# PIC32CX5109BZ31048_SL3 register map
Vendor: Microchip Technology; Series: PIC32CXBZ31; File version: 0
CPU: CM4 r0p1, little endian, MPU, FPU, 3 interrupt priority bits, 43 interrupts
Registers are 32-bit, read-write, reset 0x0 unless marked. A register's access mark holds for its fields unless they carry their own. Offsets are from the block's base; [hi:lo] are bit positions; lines under a group give offsets from that group; {n}, {i} and the like mark numbered series.

## EVSYS — Event System Interface
Base 0x41006000
0x00 CTRLA 8-bit — Control
  [0] SWRST — Software Reset
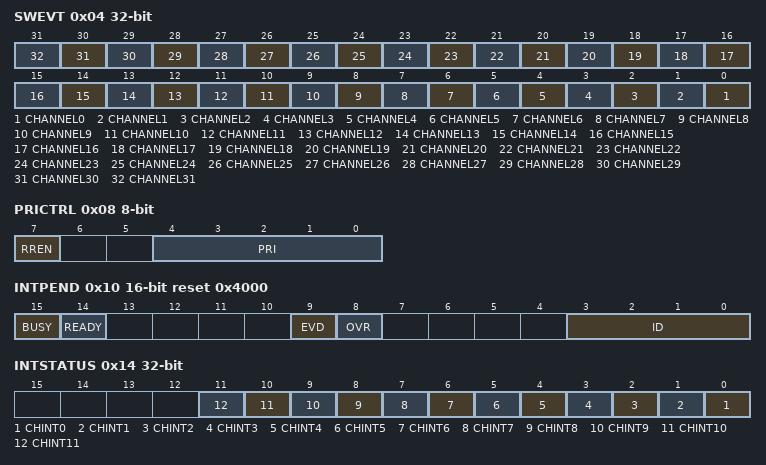
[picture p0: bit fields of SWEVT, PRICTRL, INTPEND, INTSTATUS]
0x04 SWEVT wo — Software Event
  [n] CHANNEL{n} (n=0..31) — Channel {n} Software Selection
0x08 PRICTRL 8-bit — Priority Control
  [7] RREN — Round-Robin Scheduling Enable
  [4:0] PRI — Channel Priority Number
0x10 INTPEND 16-bit reset 0x4000 — Channel Pending Interrupt
  [15] BUSY
  [14] READY
  [9] EVD — Channel Event Detected
  [8] OVR — Channel Overrun
  [3:0] ID — Channel ID
0x14 INTSTATUS ro — Interrupt Status
  [n] CHINT{n} (n=0..11) — Channel {n} Pending Interrupt
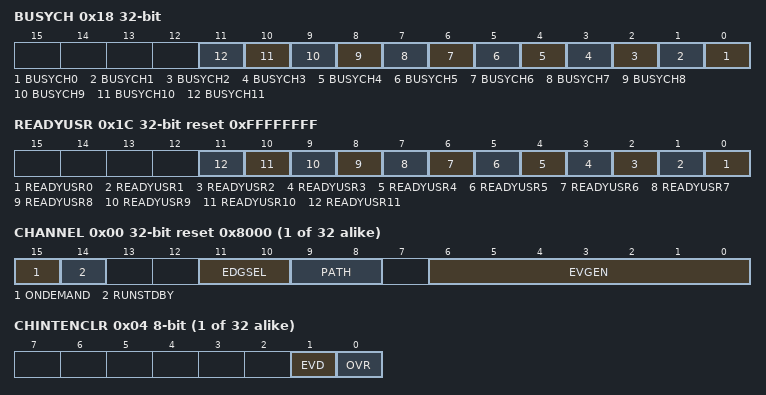
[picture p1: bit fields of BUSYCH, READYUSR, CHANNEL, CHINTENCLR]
0x18 BUSYCH ro — Busy Channels
  [n] BUSYCH{n} (n=0..11) — Busy Channel {n}
0x1C READYUSR ro reset 0xFFFFFFFF — Ready Users
  [n] READYUSR{n} (n=0..11) — Ready User for Channel {n}
{0x20+8i} CHANNEL[{i}] (i=0..31) group
  0x00 CHANNEL reset 0x8000 — Channel n Control
    [15] ONDEMAND — Generic Clock On Demand
    [14] RUNSTDBY — Run in standby
    [11:10] EDGSEL — Edge Detection Selection
      0=NO_EVT_OUTPUT (No event output when using the resynchronized or synchronous path); 1=RISING_EDGE (Event detection only on the rising edge of the signal from the event generator when using the resynchronized or synchronous path); 2=FALLING_EDGE (Event detection only on the falling edge of the signal from the event generator when using the resynchronized or synchronous path); 3=BOTH_EDGES (Event detection on rising and falling edges of the signal from the event generator when using the resynchronized or synchronous path)
    [9:8] PATH — Path Selection
      0=SYNCHRONOUS (Synchronous path); 1=RESYNCHRONIZED (Resynchronized path); 2=ASYNCHRONOUS (Asynchronous path)
    [6:0] EVGEN — Event Generator Selection
  0x04 CHINTENCLR 8-bit write-1-clears — Channel n Interrupt Enable Clear
    [1] EVD — Channel Event Detected Interrupt Disable
    [0] OVR — Channel Overrun Interrupt Disable
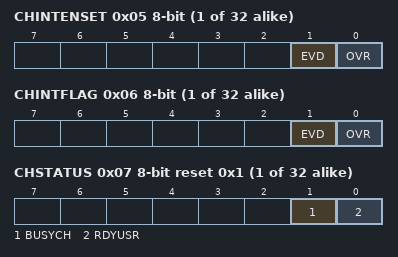
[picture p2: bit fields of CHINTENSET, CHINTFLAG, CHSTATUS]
  0x05 CHINTENSET 8-bit write-1-sets — Channel n Interrupt Enable Set
    [1] EVD — Channel Event Detected Interrupt Enable
    [0] OVR — Channel Overrun Interrupt Enable
  0x06 CHINTFLAG 8-bit write-1-clears — Channel n Interrupt Flag Status and Clear
    [1] EVD — Channel Event Detected
    [0] OVR — Channel Overrun
  0x07 CHSTATUS 8-bit ro reset 0x1 — Channel n Status
    [1] BUSYCH — Busy Channel
    [0] RDYUSR — Ready User
{0x120+4i} USER[{i}] (i=0..56) — User Multiplexer n
  [5:0] CHANNEL — Channel Event Selection

## FPU — Floating Point Unit
Base 0xE000EF30
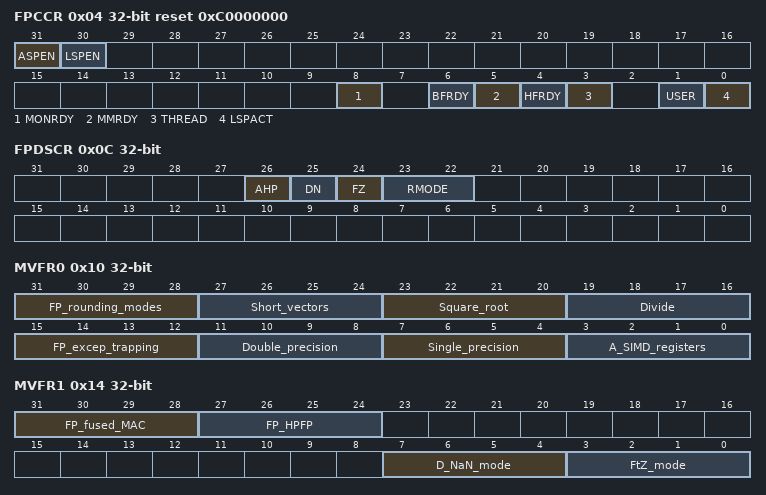
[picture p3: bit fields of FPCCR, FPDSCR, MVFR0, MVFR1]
0x04 FPCCR reset 0xC0000000 — Floating-Point Context Control Register
  [31] ASPEN, [30] LSPEN, [8] MONRDY, [6] BFRDY, [5] MMRDY, [4] HFRDY, [3] THREAD, [1] USER, [0] LSPACT
0x08 FPCAR — Floating-Point Context Address Register
  [31:3] ADDRESS — Address for FP registers in exception stack frame
0x0C FPDSCR — Floating-Point Default Status Control Register
  [26] AHP — Default value for FPSCR.AHP
  [25] DN — Default value for FPSCR.DN
  [24] FZ — Default value for FPSCR.FZ
  [23:22] RMODE — Default value for FPSCR.RMODE
    0=RN (Round to Nearest); 1=RP (Round towards Positive Infinity); 2=RM (Round towards Negative Infinity); 3=RZ (Round towards Zero)
0x10 MVFR0 ro — Media and FP Feature Register 0
  [31:28] FP_rounding_modes, [27:24] Short_vectors, [23:20] Square_root, [19:16] Divide, [15:12] FP_excep_trapping, [11:8] Double_precision, [7:4] Single_precision, [3:0] A_SIMD_registers
0x14 MVFR1 ro — Media and FP Feature Register 1
  [31:28] FP_fused_MAC, [27:24] FP_HPFP, [7:4] D_NaN_mode, [3:0] FtZ_mode

## FREQM — Frequency Meter
Base 0x40000400
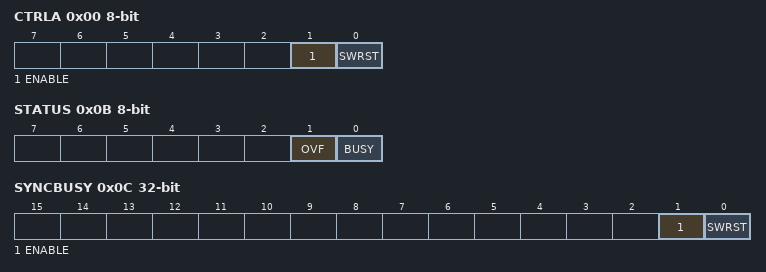
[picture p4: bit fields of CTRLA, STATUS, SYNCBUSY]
0x00 CTRLA 8-bit — Control A Register
  [1] ENABLE
  [0] SWRST — Software Reset
0x01 CTRLB 8-bit wo — Control B Register
  [0] START — Start Measurement
0x02 CFGA 16-bit — Config A register
  [7:0] REFNUM — Number of Reference Clock Cycles
0x08 INTENCLR 8-bit write-1-clears — Interrupt Enable Clear Register
  [0] DONE — Measurement Done Interrupt Enable
0x09 INTENSET 8-bit write-1-sets — Interrupt Enable Set Register
  [0] DONE — Measurement Done Interrupt Enable
0x0A INTFLAG 8-bit write-1-clears — Interrupt Flag Register
  [0] DONE — Measurement Done
0x0B STATUS 8-bit
  [1] OVF — Sticky Count Value Overflow
  [0] BUSY — FREQM Status
0x0C SYNCBUSY ro — Synchronization Busy Register
  [1] ENABLE
  [0] SWRST — Software Reset
0x10 VALUE ro — Count Value Register
  [23:0] VALUE — Measurement Value
